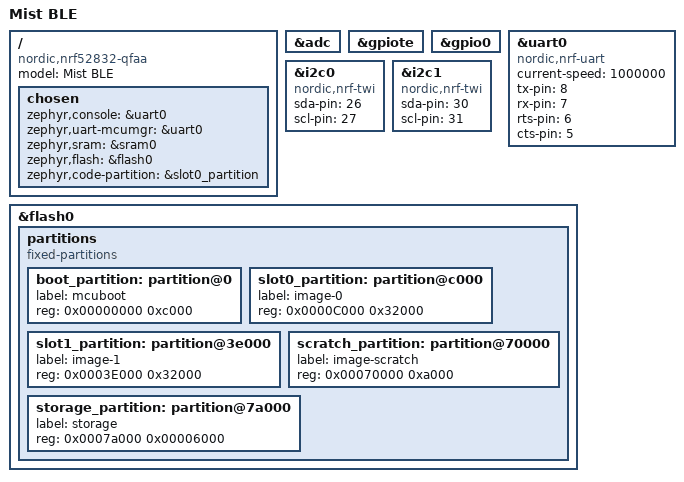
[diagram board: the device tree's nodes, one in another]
/*
 * Copyright (c) 2017 Shawn Nock <shawn@monadnock.ca>
 * Copyright (c) 2017 Linaro Limited
 *
 * SPDX-License-Identifier: Apache-2.0
 */

/dts-v1/;
#include <nordic/nrf52832_qfaa.dtsi>

/ {
	model = "Mist BLE";
	compatible = "nordic,nrf52832-qfaa", "nordic,nrf52832";

	chosen {
		zephyr,console = &uart0;
		zephyr,uart-mcumgr = &uart0;
		zephyr,sram = &sram0;
		zephyr,flash = &flash0;
		zephyr,code-partition = &slot0_partition;
	};
};

&adc {
	status = "okay";
};

&gpiote {
	status = "okay";
};

&gpio0 {
	status = "okay";
};

&uart0 {
	status = "okay";
	compatible = "nordic,nrf-uart";
	current-speed = <1000000>;
	tx-pin = <8>;
	rx-pin = <7>;
	rts-pin = <6>;
	cts-pin = <5>;
};

&i2c0 {
	compatible = "nordic,nrf-twi";
	status = "okay";
	sda-pin = <26>;
	scl-pin = <27>;
};

&i2c1 {
	compatible = "nordic,nrf-twi";
	status = "okay";
	sda-pin = <30>;
	scl-pin = <31>;
};

&flash0 {
	/*
	 * For more information, see:
	 * http://docs.zephyrproject.org/devices/dts/flash_partitions.html
	 */
	partitions {
		compatible = "fixed-partitions";
		#address-cells = <1>;
		#size-cells = <1>;

		boot_partition: partition@0 {
			label = "mcuboot";
			reg = <0x00000000 0xc000>;
		};
		slot0_partition: partition@c000 {
			label = "image-0";
			reg = <0x0000C000 0x32000>;
		};
		slot1_partition: partition@3e000 {
			label = "image-1";
			reg = <0x0003E000 0x32000>;
		};
		scratch_partition: partition@70000 {
			label = "image-scratch";
			reg = <0x00070000 0xa000>;
		};
		storage_partition: partition@7a000 {
			label = "storage";
			reg = <0x0007a000 0x00006000>;
		};
	};
};
